# MMCSD_MMC_48300000h register map
Vendor: Texas Instruments
Peripheral module from a debugger description file (folder AM261x).
Registers are 32-bit, access per field, reset values left out (the file's numbers can be read two ways) unless marked. A register's access mark holds for its fields unless they carry their own. Offsets are as the file gives them; lines under a group give offsets from that group; [hi:lo] are bit positions; {n}, {i} and the like mark numbered series; 'fields as' and 'values as' point back to an identical list; <NAME> marks a mode.

## MMC (part 1 of 3)
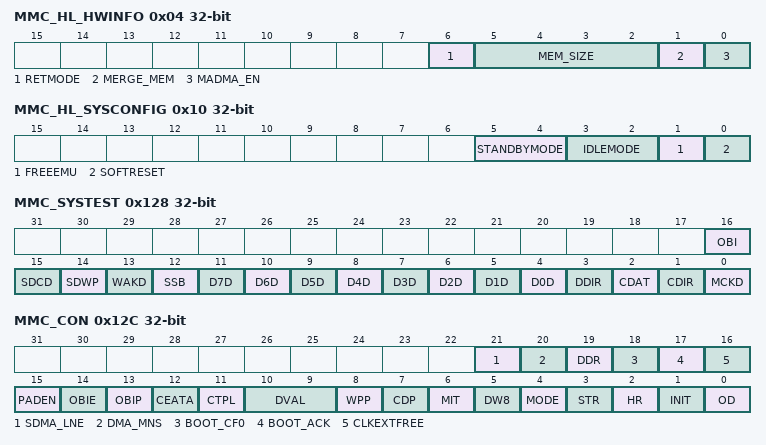
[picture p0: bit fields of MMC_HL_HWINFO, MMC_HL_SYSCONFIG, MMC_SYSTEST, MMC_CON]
0x04 MMC_HL_HWINFO ro — Information about the IP module's hardware configuration, i.e. typically the module's HDL generics (if any).Actual field format and encoding is up to the module's designer to decide.
  [6] RETMODE — Retention Mode generic parameterThis bit field indicates whether the retention mode is supported using the pin PIRFFRET. 0 Retention mode disabled1 Retention mode enabled
  [5:2] MEM_SIZE — Memory size for FIFO buffer: 1 Memory of 512 bytes, max block length is 512 bytes2 Memory of 1024 bytes, max block length is 1024 bytes4 Memory of 2048 bytes, max block length is 2048 bytes8 Memory of 4096 bytes, max block length is 2048 bytes
  [1] MERGE_MEM — Memory merged for FIFO buffer:This register defines the configuration of FIFO buffer architecture. If the bit is set STA and DFT shall support clock multiplexing and balancing. 0 2 memories instantiated, one per data transfer direction.1 A single memory is used with multiplexed addresses, data and clocks.
  [0] MADMA_EN — Master DMA enabled generic parameter:This register defines the configuration of the controller to know if it supports the master DMA management called ADMA. 0 No Master DMA (ADMA) management supported1 Controller supports ADMA
0x10 MMC_HL_SYSCONFIG — Clock Management Configuration Register.
  [5:4] STANDBYMODE rw — Configuration of the local initiator state management mode.By definition, initiator may generate read/write transaction as long as it is out of STANDBY state. 0 Force-standby mode: local initiator is unconditionally placed in standby state.Backup mode, for debug only.1 No-standby mode: local initiator is unconditionally placed out of standby state.Backup mode, for debug only.2 Smart-standby mode: local initiator standby status depends on local conditions, i.e. the module's functional requirement from the initiator.IP module shall not generate (initiator-related) wakeup events.3 Smart-Standby wakeup-capable mode: local initiator standby status depends on local conditions, i.e. the module's functional requirement from the initiator. IP module may generate (master-related) wakeup events when in standby state.Mode is only relevant if the appropriate IP module 'mwakeup' output is implemented.
  [3:2] IDLEMODE rw — Configuration of the local target state management mode.By definition, target can handle read/write transaction as long as it is out of IDLE state. 0 Force-idle mode: local target's idle state follows (acknowledges) the system's idle requests unconditionally, i.e. regardless of the IP module's internal requirements.Backup mode, for debug only.1 No-idle mode: local target never enters idle state.Backup mode, for debug only.2 Smart-idle mode: local target's idle state eventually follows (acknowledges) the system's idle requests, depending on the IP module's internal requirements.IP module shall not generate (IRQ- or DMA-request- related) wakeup events.3 Smart-idle wakeup-capable mode: local target's idle state eventually follows (acknowledges) the system's idle requests, depending on the IP module's internal requirements.IP module may generate (IRQ- or DMA-request-related) wakeup events when in idle state.Mode is only relevant if the appropriate IP module 'swakeup' output(s) is (are) implemented.
  [1] FREEEMU rw — Sensitivity to emulation [debug] suspend input signal.Functionality NOT implemented in MMCSD. 0 IP module is sensitive to emulation suspend1 IP module is not sensitive to emulation suspend
  [0] SOFTRESET rw — Software reset. [Optional] 0 No action0 Reset done, no pending action1 Reset (software or other) ongoing1 Initiate software reset
0x114 MMC_SYSSTATUS ro — System Status RegisterThis register provides status information about the module excluding the interrupt status information.
  [0] RESETDONE — Internal Reset MonitoringNote: the debounce clock , the system clock [OCP] and the functional clock shall be provided to the MMC/SD/SDIO host controller to allow the internal reset monitoring. 0 Internal module reset is on-going1 Reset completed.
0x124 MMC_CSRE rw — Card Status Response Error This register enables the host controller to detect card status errors of response type R1, R1b for all cards and of R5, R5b and R6 response for cards types SD or SDIO. When a bit MMCHS_CSRE[i] is set to 1, if the corresponding bit at the same position in the response MMCHS_RSP0[i] is set to 1, the host controller indicates a card error (MMCHS_STAT[CERR]) interrupt status to avoid the host driver reading the response register (MMCHS_RSP0). Note: No automatic card error detection for autoCMD12 is implemented; the host system has to check autoCMD12 response register (MMCHS_RESP76) for possible card errors.
  [31:0] CSRE — Card status response error
0x128 MMC_SYSTEST — System Test Register This register is used to control the signals that connect to I/O pins when the module is configured in system test (SYSTEST) mode for boundary connectivity verification. Note: In SYSTEST mode, a write into MMCHS_CMD register will not start a transfer. The buffer behaves as a stack accessible only by the local host (push and pop operations). In this mode, the Transfer Block Size (MMCHS_BLK[BLEN]) and the Blocks count for current transfer (MMCHS_BLK[NBLK]) are needed to generate a Buffer write ready interrupt (MMCHS_STAT[BWR]) or a Buffer read ready interrupt (MMCHS_STAT[BRR]) and DMA requests if enabled.
  [16] OBI ro — Out-Of-Band Interrupt [OBI] data value 0 The Out-of-Band Interrupt pin is driven low.1 The Out-of-Band Interrupt pin is driven high.
  [15] SDCD ro — Card detect input signal [SDCD] data value 0 The card detect pin is driven low.1 The card detect pin is driven high.
  [14] SDWP ro — Write protect input signal [SDWP] data value 0 The write protect pin SDWP is driven low.1 The write protect pin SDWP is driven high.
  [13] WAKD rw — Wake request output signal data value 0 The pin SWAKEUP is driven low.0 No action. Returns 0.1 The pin SWAKEUP is driven high.1 No action. Returns 1.
  [12] SSB rw — Set status bitThis bit must be cleared prior attempting to clear a status bit of the interrupt status register [MMCSD_STAT]. 0 Clear this SSB bitfield. Writing 0 does not clear already set status bits;0 No action. Returns 0.1 No action. Returns 1.1 Force to 1 all status bits of the interrupt status register (MMCHS_STAT) only if the corresponding bitfield in the Interrupt signal enable register (MMCHS_ISE) is set.
  [n+4] D{n}D rw (n=1..7) — DAT{n} input/output signal data value 0 If SYSTEST[DDIR] = 0 (output mode direction), the DAT{n} line is driven low. If SYSTEST[DDIR] = 1 (input mode direction), no effect.0 If SYSTEST[DDIR] = 1 (input mode direction), returns the value on the DAT{n} line (low). If SYSTEST[DDIR] = 0 (output mode direction), returns 01 If SYSTEST[DDIR] = 0 (output mode direction), the DAT{n} line is driven high. If SYSTEST[DDIR] = 1 (input mode direction), no effect.1 If SYSTEST[DDIR] = 1 (input mode direction), returns the value on the DAT{n} line (high) If SYSTEST[DDIR] = 0 (output mode direction), returns 1
  [4] D0D rw — DAT0 input/output signal data value 0 If SYSTEST[DDIR] = 1 (input mode direction), returns the value on the DAT0 line (low). If SYSTEST[DDIR] = 0 (output mode direction), returns 00 If SYSTEST[DDIR] = 0 (output mode direction), the DAT0 line is driven low. If SYSTEST[DDIR] = 1 (input mode direction), no effect.1 If SYSTEST[DDIR] = 0 (output mode direction), the DAT0 line is driven high. If SYSTEST[DDIR] = 1 (input mode direction), no effect.1 If SYSTEST[DDIR] = 1 (input mode direction), returns the value on the DAT0 line (high) If SYSTEST[DDIR] = 0 (output mode direction), returns 1
  [3] DDIR rw — Control of the DAT[7:0] pins direction. 0 The DAT lines are outputs (host to card)0 No action. Returns 0.1 The DAT lines are inputs (card to host)1 No action. Returns 1.
  [2] CDAT rw — CMD input/output signal data value 0 If SYSTEST[CDIR] = 0 (output mode direction), the CMD line is driven low. If SYSTEST[CDIR] = 1 (input mode direction), no effect.0 If SYSTEST[CDIR] = 1 (input mode direction), returns the value on the CMD line (low). If SYSTEST[CDIR] = 0 (output mode direction), returns 01 If SYSTEST[CDIR] = 0 (output mode direction), the CMD line is driven high. If SYSTEST[CDIR] = 1 (input mode direction), no effect.1 If SYSTEST[CDIR] = 1 (input mode direction), returns the value on the CMD line (high) If SYSTEST[CDIR] = 0 (output mode direction), returns 1
  [1] CDIR rw — Control of the CMD pin direction. 0 The CMD line is an output (host to card)0 No action. Returns 0.1 The CMD line is an input (card to host)1 No action. Returns 1.
  [0] MCKD rw — MMC clock output signal data value 0 The output clock is driven low.0 No action. Returns 0.1 The output clock is driven high.1 No action. Returns 1.
0x12C MMC_CON — Configuration Register This register is used: - to select the functional mode or the SYSTEST mode for any card. - to send an initialization sequence to any card. - to enable the detection on DAT[1] of a card interrupt for SDIO cards only. and also to configure : - specific data and command transfers for MMC cards only. - the parameters related to the card detect and write protect input signals.
  [21] SDMA_LNE rw — Target DMA Level/Edge Request:The waveform of the DMA request can be configured either edge sensitive with early de-assertion on first access to MMCSD_DATA register or late de-assertion, request remains active until last allowed data written into MMCSD_DATA. 0 Slave DMA edge sensitive, Early DMA de- assertion1 Slave DMA level sensitive, Late DMA de- assertion
  [20] DMA_MNS rw — DMA Master or Target selection:When this bit is set and the controller is configured to use the DMA, Ocp master interface is used to get datas from system using ADMA2 procedure [direct access to the memory].This option is only available if generic parameter MADMA_EN is asserted to '1'. 0 The controller is slave on data transfers with system.1 The controller is master on data exchange with system, controller must be configured as using DMA.
  [19] DDR rw — Dual Data Rate mode:When this register is set, the controller uses both clock edge to emit or receive data. Odd bytes are transmitted on falling edges and even bytes are transmitted on rise edges. It only applies on Data bytes and CRC, Start, end bits and CRC status are kept full cycle.This bit field is only meaningful and active for even clock divider ratio of MMCSD_SYSCTL[CLKD], it is insensitive to MMCSD_HCTL[HSPE] setting. 0 Standard mode : data are transmitted on a single edge depending on MMCHS_HCTRL[HSPE].1 Data Bytes and CRC are transmitted on both edge.
  [18] BOOT_CF0 rw — Boot status supported:This register is set when the CMD line need to be forced to '0' for a boot sequence. CMD line is driven to '0' after Writing in MMCSD_CMD. The line is released when this bit field is de-asserted and abort data transfer in case of a pending transaction. 0 CMD line is released when it was previously forced to '0' by a boot sequence.0 CMD line not forced1 CMD line forced to '0' is enabled and will be active after writing into MMCHS_CMD1 CMD line forced to '0' is enabled
  [17] BOOT_ACK rw — Book acknowledge received:When this bit is set the controller should receive a boot status on DAT0 line after next command issued. If no status is received a data timeout will be generated. 0 No acknowledge to be received1 A boot status will be received on DAT0 line after issuing a command.
  [16] CLKEXTFREE rw — External clock free running:This register is used to maintain card clock out of transfer transaction to enable target module for example to generate a synchronous interrupt on DAT[1]. The Clock will be maintain only if MMCSD_SYSCTL[CEN] is set. 0 External card clock is cut off outside active transaction period.1 External card clock is maintain even out of active transaction period only if MMCHS_SYSCTL[CEN] is set.
  [15] PADEN rw — Control Power for MMC Lines:This register is only useful when MMC PADs contain power saving mechanism to minimize its leakage power. It works as a GPIO that directly control the ACTIVE pin of PADs. Excepted for DAT[1], the signal is also combine outside the module with the dedicated power control MMCSD_CON[CTPL] bit. 0 ADPIDLE module pin is not forced, it is automatically generated by the MMC fsms.1 ADPIDLE module pin is forced to active state.
  [14] OBIE rw — Out-of-Band Interrupt EnableMMC cards only:This bit enables the detection of Out-of-Band Interrupt on MMCOBI input pin.The usage of the Out-of-Band signal [OBI] is optional and depends on the system integration. 0 Out-of-Band interrupt detection disabled1 Out-of-Band interrupt detection enabled
  [13] OBIP rw — Out-of-Band Interrupt PolarityMMC cards only:This bit selects the active level of the out-of-band interrupt coming from MMC cards.The usage of the Out-of-Band signal [OBI] is optional and depends on the system integration. 0 Active high level1 Active low level
  [12] CEATA rw — CE-ATA control modeMMC cards compliant with CE-ATA:By default, this bit is set to 0. It is use to indicate that next commands are considered as specific CE-ATA commands that potentially use 'command completion' features. 0 Standard MMC/SD/SDIO mode.1 CE-ATA mode next commands are considered as CE-ATA commands.
  [11] CTPL rw — Control Power for DAT[1] lineMMC and SD cards:By default, this bit is set to 0 and the host controller automatically disables all the input buffers outside of a transaction to minimize the leakage current. SDIO cards:When this bit is set to 1, the host controller automatically disables all the input buffers except the buffer of DAT[1] outside of a transaction in order to detect asynchronous card interrupt on DAT[1] line and minimize the leakage current of the buffers. 0 Disable all the input buffers outside of a transaction.1 Disable all the input buffers except the buffer of DAT[1] outside of a transaction.
  [10:9] DVAL rw — Debounce filter valueAll cardsThis register is used to define a debounce period to filter the card detect input signal [SDCD].The usage of the card detect input signal [SDCD] is optional and depends on the system integration and the type of the connector housing that accommodates the card. 0 33 us debounce period1 231 us debounce period2 1 ms debounce period3 8,4 ms debounce period
  [8] WPP rw — Write protect polarityFor SD and SDIO cards onlyThis bit selects the active level of the write protect input signal [SDWP].The usage of the write protect input signal [SDWP] is optional and depends on the system integration and the type of the connector housing that accommodates the card. 0 Active high level1 Active low level
  [7] CDP rw — Card detect polarityAll cardsThis bit selects the active level of the card detect input signal [SDCD]. The usage of the card detect input signal [SDCD] is optional and depends on the system integration and the type of the connector housing that accommodates the card. 0 Active low level1 Active high level
  [6] MIT rw — MMC interrupt commandOnly for MMC cards.This bit must be set to 1, when the next write access to the command register [MMCSD_CMD] is for Writing a MMC interrupt command [CMD40] requiring the command timeout detection to be disabled for the command response. 0 Command timeout enabled1 Command timeout disabled
  [5] DW8 rw — 8-bit mode MMC selectFor SD/SDIO cards, this bit must be set to 0. For MMC card,this bit must be set following a valid SWITCH command [CMD6] with the correct value and extend CSD index written in the argument. Prior to this command, the MMC card configuration register [CSD and EXT_CSD] must be verified for compliancy with MMC standard specification 4.x [see section 3.6]. 0 1-bit or 4-bit Data width (DAT[0] used, MMC, SD cards)1 8-bit Data width (DAT[7:0] used, MMC cards)
  [4] MODE rw — Mode selectAll cardsThese bits select between Functional mode and SYSTEST mode. 0 Functional mode. Transfers to the MMC/SD/SDIO cards follow the card protocol. MMC clock is enabled. MMC/SD transfers are operated under the control of the CMD register.1 SYSTEST mode The signal pins are configured as general-purpose input/output and the 1024-byte buffer is configured as a stack memory accessible only by the local host or system DMA. The pins retain their default type (input, output or in-out). SYSTEST mode is operated under the control of the SYSTEST register.
  [3] STR rw — Stream commandOnly for MMC cards.This bit must be set to 1 only for the stream data transfers [read or write] of the adtc commands.Stream read is a class 1 command [CMD11: READ_DAT_UNTIL_STOP].Stream write is a class 3 command [CMD20: WRITE_DAT_UNTIL_STOP]. 0 Block oriented data transfer1 Stream oriented data transfer
  [2] HR rw — Broadcast host responseOnly for MMC cards.This register is used to force the host to generate a 48-bit response for bc command type.It can be used to terminate the interrupt mode by generating a CMD40 response by the core [see section 4.3, 'Interrupt Mode', in the MMC [1] specification]. In order to have the host response to be generated in open drain mode, the register MMCSD_CON[OD] must be set to 1.When MMCSD_CON[CEATA] is set to 1 and MMCSD_ARG set to 0x00000000 when Writing 0x00000000 into MMCSD_CMD register, the host controller performs a 'command completion signal disable' token i.e. CMD line held to '0' during 47 cycles followed by a 1. 0 The host does not generate a 48-bit response instead of a command.1 The host generates a 48-bit response instead of a command or a command completion signal disable token.
  [1] INIT rw — Send initialization streamAll cards.When this bit is set to 1, and the card is idle, an initialization sequence is sent to the card.An initialization sequence consists of setting the CMD line to 1 during 80 clock cycles. The initialization sequence is mandatory - but it is not required to do it through this bit - this bit makes it easier. Clock divider [MMCSD_SYSCTL[CLKD]] should be set to ensure that 80 clock periods are greater than 1ms. [see section 9.3, 'Power-Up', in the MMC card specification [1], or section 6.4 in the SD card specification [2]]. Note: in this mode, there is no command sent to the card and no response is expected 0 The host does not send an initialization sequence.1 The host sends an initialization sequence.
  [0] OD rw — Card open drain mode.Only for MMC cards.This bit must be set to 1 for MMC card commands 1, 2, 3 and 40, and if the MMC card bus is operating in open-drain mode during the response phase to the command sent. Typically, during card identification mode when the card is either in idle, ready or ident state.It is also necessary to set this bit to 1, for a broadcast host response [see Broadcast host response register MMCSD_CON[HR]] 0 No Open Drain1 Open Drain or Broadcast host response
0x130 MMC_PWCNT — Power Counter Register This register is used to program a mmc counter to delay command transfers after activating the PAD power, this value depends on PAD characteristics and voltage.
  [15:0] PWRCNT rw — Power counter register.This register is used to introduce a delay between the PAD ACTIVE pin assertion and the command issued. 0 No additional delay added1 TCF delay (card clock period)2 TCF x 2 delay (card clock period)65534 TCF x 65534 delay (card clock period)65535 TCF x 65535 delay (card clock period)
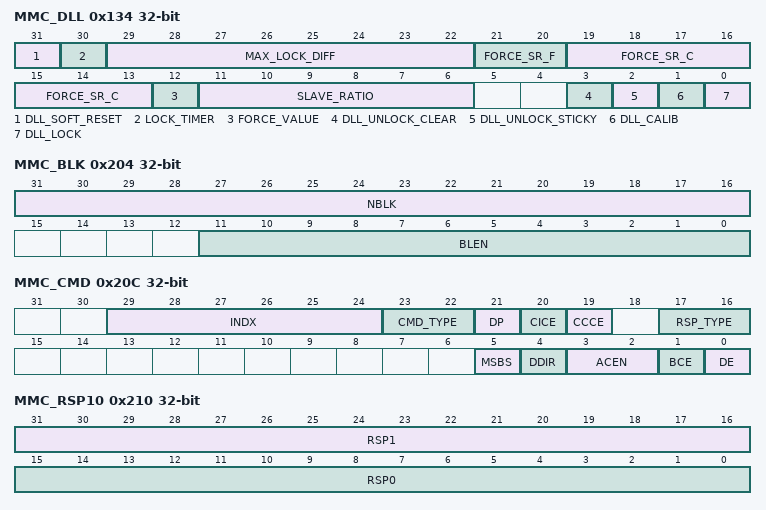
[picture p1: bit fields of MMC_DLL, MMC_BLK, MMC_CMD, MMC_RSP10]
0x134 MMC_DLL — DLL control and status register This register is used for tuning procedure required for SDR104 speed mode. It gives visibility and control on the DLL.
  [31] DLL_SOFT_RESET rw — Soft reset for DLL, active HIGH. 0 Reset completed.0 No action.1 Reset is in progress1 Issue soft reset
  [30] LOCK_TIMER rw — Timer for the dll_lock signal to be asserted after reset. 0 1024 cycles (equivalent to DLL fast mode lock)1 66560 cycles
  [29:22] MAX_LOCK_DIFF rw — Maximum number of taps that the master DLLs clock period measurement can deviate without resulting in the master DLL losing lock.
  [21:20] FORCE_SR_F rw — Forced fine delay value.
  [19:13] FORCE_SR_C rw — Forced coarse delay value
  [12] FORCE_VALUE rw — Put forced values to target DLL, ignoring master DLL output and ratio value. 0 Do not put force value1 Put force value.
  [11:6] SLAVE_RATIO rw — Fraction of a clock cycle for the shift to be implemented, in units of 256ths of a clock cycle. 0 0 degree delay2 45 degrees delay4 90 degrees delay6 135 degrees delay8 180 degrees delay10 225 degrees delay12 270 degrees delay14 315 degrees delay16 Full clock delay63 4 clocks delay
  [3] DLL_UNLOCK_CLEAR rw — Clears the phy_reg_status_mdll_unlock_sticky flags of the DLL. 0 No effect.1 Clears the flag.
  [2] DLL_UNLOCK_STICKY ro — Asserted when any single period measurement exceeds MAX_LOCK_DIFF.
  [1] DLL_CALIB rw — Enables Target DLL to update new delay values. 0 Disabled1 Enabled
  [0] DLL_LOCK ro — Master DLL lock status. 0 DLL is not locked1 DLL is locked
0x200 MMC_SDMASA rw — SDMA System Address / Argument 2 Register.
  [31:0] SDMA_ARG2 — SDMA System Address / Argument 2 This register contains the physical system memory address used for DMA transfers or the second argument for the Auto CMD23. [1] SDMA System Address This register contains the system memory address for a SDMA transfer. When the Host Controller stops a SDMA transfer, this register shall point to the system address of the next contiguous data position. It can be accessed only if no transaction is executing [i.e., after a transaction has stopped]. Read operations during transfers may return an invalid value. The Host Driver shall initialize this register before starting a SDMA transaction. After SDMA has stopped, the next system address of the next contiguous data position can be read from this register. The SDMA transfer waits at the every boundary specified by the Host SDMA Buffer Boundary in the Block Size register. The Host Controller generates DMA Interrupt to request the Host Driver to update this register. The Host Driver sets the next system address of the next data position to this register. When the most upper byte of this register 003h is written, the Host Controller restarts the SDMA transfer. When restarting SDMA by the Resume command or by setting Continue Request in the Block Gap Control register, the Host Controller shall start at the next contiguous address stored here in the SDMA System Address register. ADMA does not use this register. [2] Argument 2 This register is used with the Auto CMD23 to set a 32-bit block count value to the argument of the CMD23 while executing Auto CMD23. If Auto CMD23 is used with ADMA, the full 32-bit block count value can be used. If Auto CMD23 is used without AMDA, the available block count value is limited by the Block Count register. 65535 blocks is the maximum value in this case.
0x204 MMC_BLK — Transfer Length Configuration Register MMCHS_BLK[BLEN] is the block size register. MMCHS_BLK[NBLK] is the block count register. This register shall be used for any card.
  [31:16] NBLK rw — Blocks count for current transferThis register is enabled when Block count Enable [MMCSD_CMD[BCE]] is set to 1 and is valid only for multiple block transfers. Setting the block count to 0 results no data blocks being transferred.Note: The host controller decrements the block count after each block transfer and stops when the count reaches zero.This register can be accessed only if no transaction is executing [i.e, after a transaction has stopped]. Read operations during transfers may return an invalid value and write operation will be ignored.In suspend context, the number of blocks yet to be transferred can be determined by Reading this register. When restoring transfer context prior to issuing a Resume command, The local host shall restore the previously saved block count. 0 Stop count1 1 block2 2 blocks65535 65535 blocks
  [11:0] BLEN rw — Transfer Block Size.This register specifies the block size for block data transfers.Read operations during transfers may return an invalid value, and write operations are ignored.When a CMD12 command is issued to stop the transfer, a read of the BLEN field after transfer completion [MMCSD_STAT[TC] set to 1] will not return the true byte number of data length while the stop occurs but the value written in this register before transfer is launched. 0 No data transfer1 1 byte block length2 2 bytes block length3 3 bytes block length511 511 bytes block length512 512 bytes block length2047 2047 bytes block length2048 2048 bytes block length
0x208 MMC_ARG rw — Command Argument Register This register contains command argument specified as bit 39-8 of Command-Format These registers must be initialized prior to sending the command itself to the card (write action into the register MMCHS_CMD register). Only exception is for a command index specifying stuff bits in arguments, making a write unnecessary.
  [31:0] ARG — Command argument bits [31:0]
0x20C MMC_CMD — Command and Transfer Mode Register MMCHS_CMD[31:16] = the command register MMCHS_CMD[15:0] = the transfer mode. This register configures the data and command transfers. A write into the most significant byte send the command. A write into MMCHS_CMD[15:0] registers during data transfer has no effect. This register shall be used for any card. Note: In SYSTEST mode, a write into MMCHS_CMD register will not start a transfer.
  [29:24] INDX rw — Command indexBinary encoded value from 0 to 63 specifying the command number send to card 0 CMD0 or ACMD01 CMD1 or ACMD12 CMD2 or ACMD23 CMD3 or ACMD34 CMD4 or ACMD45 CMD5 or ACMD56 CMD6 or ACMD67 CMD7 or ACMD78 CMD8 or ACMD89 CMD9 or ACMD910 CMD10 or ACMD1011 CMD11 or ACMD1112 CMD12 or ACMD1213 CMD13 or ACMD1314 CMD14 or ACMD1415 CMD15 or ACMD1516 CMD16 or ACMD1617 CMD17 or ACMD1718 CMD18 or ACMD1819 CMD19 or ACMD1920 CMD20 or ACMD2021 CMD21 or ACMD2122 CMD22 or ACMD2223 CMD23 or ACMD2324 CMD24 or ACMD2425 CMD25 or ACMD2526 CMD26 or ACMD2627 CMD27 or ACMD2728 CMD28 or ACMD2829 CMD29 or ACMD2930 CMD30 or ACMD3031 CMD31 or ACMD3132 CMD32 or ACMD3233 CMD33 or ACMD3334 CMD34 or ACMD3435 CMD35 or ACMD3536 CMD36 or ACMD3637 CMD37 or ACMD3738 CMD38 or ACMD3839 CMD39 or ACMD3940 CMD40 or ACMD4041 CMD41 or ACMD4142 CMD42 or ACMD4243 CMD43 or ACMD4344 CMD44 or ACMD4445 CMD45 or ACMD4546 CMD46 or ACMD4647 CMD47 or ACMD4748 CMD48 or ACMD4849 CMD49 or ACMD4950 CMD50 or ACMD5051 CMD51 or ACMD5152 CMD52 or ACMD5253 CMD53 or ACMD5354 CMD54 or ACMD5455 CMD55 or ACMD5556 CMD56 or ACMD5657 CMD57 or ACMD5758 CMD58 or ACMD5859 CMD59 or ACMD5960 CMD60 or ACMD6061 CMD61 or ACMD6162 CMD62 or ACMD6263 CMD63 or ACMD63
  [23:22] CMD_TYPE rw — Command type This register specifies three types of special command: Suspend, Resume and Abort. These bits shall be set to00bfor all other commands. 0 Others Commands1 CMD52 for writing 'Bus Suspend' in CCCR2 CMD52 for writing 'Function Select' in CCCR3 Abort command CMD12, CMD52 for writing ' I/O Abort' in CCCR
  [21] DP rw — Data present selectThis register indicates that data is present and DAT line shall be used.It must be set to 0 in the following conditions:- command using only CMD line- command with no data transfer but using busy signal on DAT[0]- Resume command 0 Command with no data transfer1 Command with data transfer
  [20] CICE rw — Command Index check enableThis bit must be set to 1 to enable index check on command response to compare the index field in the response against the index of the command.If the index is not the same in the response as in the command, it is reported as a command index error [MMCSD_STAT[CIE] set to1]Note: The register CICE cannot be configured for an Auto CMD12, then index check is automatically checked when this command is issued. 0 Index check disable1 Index check enable
  [19] CCCE rw — Command CRC check enableThis bit must be set to 1 to enable CRC7 check on command response to protect the response against transmission errors on the bus.If an error is detected, it is reported as a command CRC error [MMCSD_STAT[CCRC] set to 1].Note: The register CCCE cannot be configured for an Auto CMD12, and then CRC check is automatically checked when this command is issued. 0 CRC7 check disable1 CRC7 check enable
  [17:16] RSP_TYPE rw — Response typeThis bits defines the response type of the command 0 No response1 Response Length 136 bits2 Response Length 48 bits3 Response Length 48 bits with busy after response
  [5] MSBS rw — Multi/Single block selectThis bit must be set to 1 for data transfer in case of multi block command.For any others command this bit shall be set to 0. 0 Single block. If this bit is 0, it is not necessary to set the register MMCHS_BLK[NBLK].1 Multi block. When Block Count is disabled (MMCHS_CMD[BCE] is set to 0) in Multiple block transfers (MMCHS_CMD[MSBS] is set to 1), the module can perform infinite transfer.
  [4] DDIR rw — Data transfer Direction SelectThis bit defines either data transfer will be a read or a write. 0 Data Write (host to card)1 Data Read (card to host)
  [3:2] ACEN rw — Auto CMD Enable - SD card only. This field determines use of auto command functions. There are two methods to stop Multiple-block read and write operation [1] Auto CMD12 Enable When this field is set to01b the Host Controller issues CMD12 automatically when last block transfer is completed. Auto CMD12 error is indicated to the Auto CMD Error Status register. The Host Driver shall not set this bit if the command does not require CMD12. In particular, secure commands defined in the Part 3 File Security specification do not require CMD12. [2] Auto CMD23 Enable When this bit field is set to10b the Host Controller issues a CMD23 automatically before issuing a command specified in the Command Register. The Host Controller Version 3.00 and later shall support this function. The following conditions are required to use the Auto CMD23. Auto CMD23 Supported [Host Controller Version is 3.00 or later] A memory card that supports CMD23 [SCR[33]=1] If DMA is used, it shall be ADMA. Only when CMD18 or CMD25 is issued [Note, the Host Controller does not check command index.] Auto CMD23 can be used with or without ADMA. By Writing the Command register, the Host Controller issues a CMD23 first and then issues a command specified by the Command Index in Command register. If response errors of CMD23 are detected, the second command is not issued. A CMD23 error is indicated in the Auto CMD Error Status register. 32-bit block count value for CMD23 is set to SDMA System Address / Argument 2 register. 0 Auto Command Disabled1 Auto CMD12 enable or CCS detection enabled.2 Auto CMD23 Enable3 Reserved
  [1] BCE rw — Block Count EnableMultiple block transfers only.This bit is used to enable the block count register [MMCSD_BLK[NBLK]].When Block Count is disabled [MMCSD_CMD[BCE] is set to 0] in Multiple block transfers [MMCSD_CMD[MSBS] is set to 1], the module can perform infinite transfer. 0 Block count disabled for infinite transfer.1 Block count enabled for multiple block transfer with known number of blocks
  [0] DE rw — DMA EnableThis bit is used to enable DMA mode for host data access. 0 DMA mode disable1 DMA mode enable
0x210 MMC_RSP10 ro — Command Response[31:0] Register This 32-bit register holds bits positions [31:0] of command response type R1/R1b/R2/R3/R4/R5/R5b/R6.
  [31:16] RSP1 — Command Response [31:16]
  [15:0] RSP0 — Command Response [15:0]
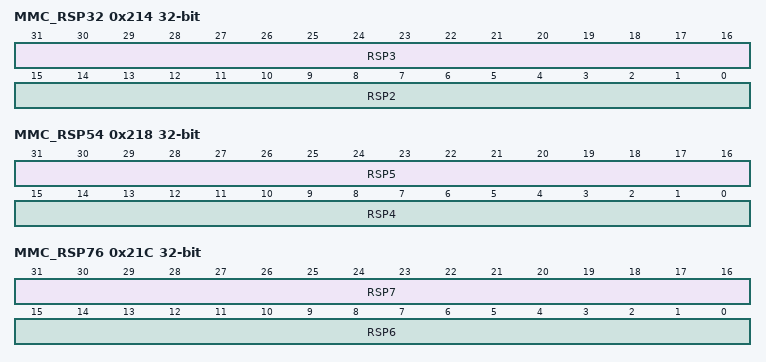
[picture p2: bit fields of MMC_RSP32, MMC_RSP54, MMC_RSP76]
0x214 MMC_RSP32 ro — Command Response[63:32] Register This 32-bit register holds bits positions [63:32] of command response type R2.
  [31:16] RSP3 — Command Response [63:48]
  [15:0] RSP2 — Command Response [47:32]
0x218 MMC_RSP54 ro — Command Response[95:64] Register This 32-bit register holds bits positions [95:64] of command response type R2.
  [31:16] RSP5 — Command Response [95:80]
  [15:0] RSP4 — Command Response [79:64]
0x21C MMC_RSP76 ro — Command Response[127:96] Register This 32-bit register holds bits positions [127:96] of command response type R1(Auto CMD23)/R1b(Auto CMD12)/R2.
  [31:16] RSP7 — Command Response [127:112]
  [15:0] RSP6 — Command Response [111:96]
